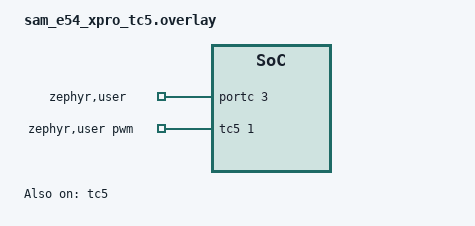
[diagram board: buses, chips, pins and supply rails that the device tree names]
/*
 * Copyright (c) 2025 Microchip Technology Inc.
 *
 * SPDX-License-Identifier: Apache-2.0
 */

/* connect the PB15 to PC03 */

#include <zephyr/dt-bindings/gpio/gpio.h>

/ {
	zephyr,user {
		pwms = <&tc5 1 PWM_MSEC(1) 0>;
		gpios = <&portc 3 GPIO_ACTIVE_HIGH>;
	};
};

&tc5 {
	status = "okay";
	compatible = "microchip,tc-g1-pwm";
	#pwm-cells = <3>;
	pinctrl-0 = <&tc5_pwm_default>;
	pinctrl-names = "default";
	prescaler = <4>;
};

&pinctrl {
	tc5_pwm_default: tc5_pwm_default {
		group1 {
			pinmux = <PB15E_TC5_WO1>;
		};
	};
};
